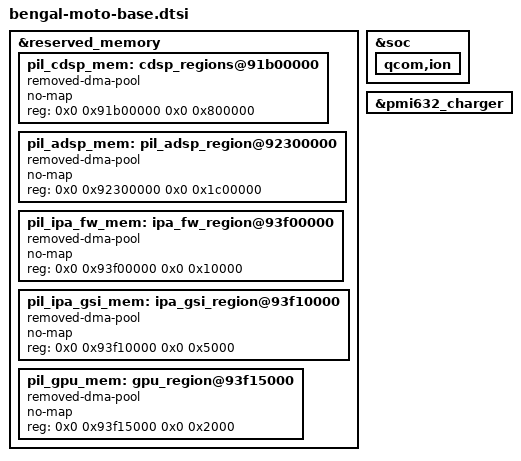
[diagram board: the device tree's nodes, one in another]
/* Copyright (c) 2020, The Linux Foundation. All rights reserved.
 *
 * This program is free software; you can redistribute it and/or modify
 * it under the terms of the GNU General Public License version 2 and
 * only version 2 as published by the Free Software Foundation.
 *
 * This program is distributed in the hope that it will be useful,
 * but WITHOUT ANY WARRANTY; without even the implied warranty of
 * MERCHANTABILITY or FITNESS FOR A PARTICULAR PURPOSE.  See the
 * GNU General Public License for more details.
 */

#include "bengal.dtsi"

/*
 * Moto huangzq2 BEGIN: Reduce cdsp caverout for all targets as it only be used by FOD feature.
 * The size in qdsp6.xml need to be changed as well.
 * - remove cdsp_sec_mem; -30M
 * - reduce pil_cdsp_mem; -22M
 */
/delete-node/ &pil_cdsp_mem;
/delete-node/ &pil_adsp_mem;
/delete-node/ &pil_ipa_fw_mem;
/delete-node/ &pil_ipa_gsi_mem;
/delete-node/ &pil_gpu_mem;
/delete-node/ &cdsp_sec_mem;

&reserved_memory {
	pil_cdsp_mem: cdsp_regions@91b00000 {
		compatible = "removed-dma-pool";
		no-map;
		reg = <0x0 0x91b00000 0x0 0x800000>;
	};

	pil_adsp_mem: pil_adsp_region@92300000 {
		compatible = "removed-dma-pool";
		no-map;
		reg = <0x0 0x92300000 0x0 0x1c00000>;
	};

	pil_ipa_fw_mem: ipa_fw_region@93f00000 {
		compatible = "removed-dma-pool";
		no-map;
		reg = <0x0 0x93f00000 0x0 0x10000>;
	};

	pil_ipa_gsi_mem: ipa_gsi_region@93f10000 {
		compatible = "removed-dma-pool";
		no-map;
		reg = <0x0 0x93f10000 0x0 0x5000>;
	};

	pil_gpu_mem: gpu_region@93f15000 {
		compatible = "removed-dma-pool";
		no-map;
		reg = <0x0 0x93f15000 0x0 0x2000>;
	};
};

&soc {
	qcom,ion {
		/delete-node/ qcom,ion-heap@14;
	};
};
/*
 * Moto huangzq2 END
 */

&pmi632_charger {
        /delete-property/ qcom,sw-jeita-enable;
        /delete-property/ qcom,step-charging-enable;
        /delete-property/ qcom,hw-die-temp-mitigation;
        /delete-property/ qcom,hw-connector-mitigation;
};
